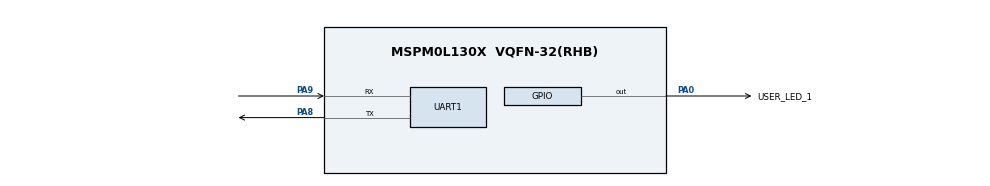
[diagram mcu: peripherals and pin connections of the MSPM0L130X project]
// @cliArgs --device "MSPM0L130X" --package "VQFN-32(RHB)" --part "Default"
// @cliArgs --board /ti/boards/LP_MSPM0L1306 --rtos nortos

/**
 * Import the modules used in this configuration.
 */
const UART   = scripting.addModule("/ti/driverlib/UART", {}, false);
const UART1  = UART.addInstance();

const GPIO   = scripting.addModule("/ti/driverlib/GPIO", {}, false);
const GPIO1  = GPIO.addInstance();

/**
 * Write custom configuration values to the imported modules.
 */

UART1.$name = "UART_0";
UART1.profile = "CONFIG_PROFILE_1";
UART1.peripheral.$assign = "UART0";
UART1.targetBaudRate = 9600;
UART1.enableInternalLoopback = false;
UART1.enabledInterrupts = ["DMA_DONE_TX", "EOT_DONE"];
UART1.enableFIFO = true;
UART1.txFifoThreshold = "DL_UART_TX_FIFO_LEVEL_ONE_ENTRY";
UART1.enabledDMATXTriggers = "DL_UART_DMA_INTERRUPT_TX";
UART1.enableDMATX          = true;

UART1.peripheral.txPin.$assign = "PA8";
UART1.peripheral.rxPin.$assign = "PA9";

UART1.DMA_CHANNEL_TX.peripheral.$assign = "DMA_CH0";
UART1.DMA_CHANNEL_TX.addressMode = "b2f";
UART1.DMA_CHANNEL_TX.srcIncDec = "INCREMENT";
UART1.DMA_CHANNEL_TX.dstLength = "BYTE";
UART1.DMA_CHANNEL_TX.srcLength = "BYTE";

GPIO1.$name                          = "GPIO_LEDS";
GPIO1.associatedPins.create(2);
GPIO1.associatedPins[0].$name        = "USER_LED_1";
GPIO1.associatedPins[0].assignedPort = "PORTA";
GPIO1.associatedPins[0].initialValue = "SET";
GPIO1.associatedPins[0].assignedPin  = "0";
GPIO1.associatedPins[0].pin.$assign  = "PA0";
GPIO1.associatedPins[1].$name        = "USER_TEST";
GPIO1.associatedPins[1].assignedPort = "PORTA";
GPIO1.associatedPins[1].assignedPin  = "1";
GPIO1.associatedPins[1].initialValue = "SET";

const SYSCTL = scripting.addModule("/ti/driverlib/SYSCTL");
SYSCTL.clockTreeEn = true;
